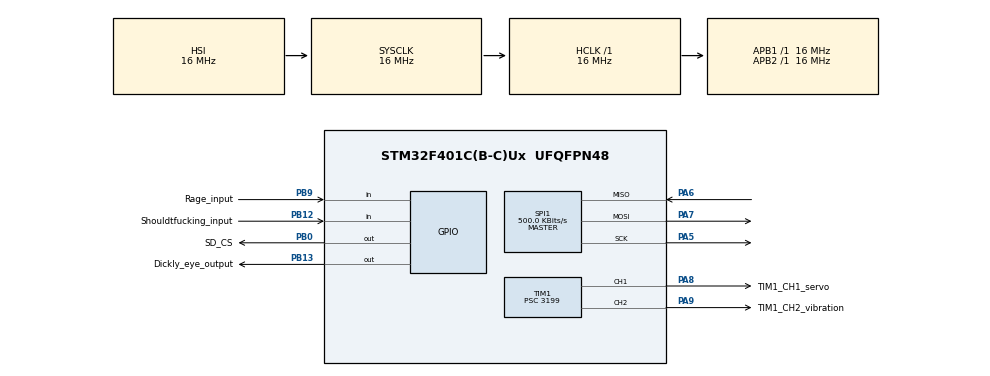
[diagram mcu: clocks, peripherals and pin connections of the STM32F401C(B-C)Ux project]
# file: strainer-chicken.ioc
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Mcu.Family=STM32F4
Mcu.Name=STM32F401C(B-C)Ux
Mcu.Package=UFQFPN48
NVIC.PriorityGroup=NVIC_PRIORITYGROUP_4
PA5.Mode=Full_Duplex_Master
PA5.Signal=SPI1_SCK
PA6.Mode=Full_Duplex_Master
PA6.Signal=SPI1_MISO
PA7.Mode=Full_Duplex_Master
PA7.Signal=SPI1_MOSI
PA8.GPIO_Label=TIM1_CH1_servo
PA8.Signal=S_TIM1_CH1
PA9.GPIO_Label=TIM1_CH2_vibration
PA9.Signal=S_TIM1_CH2
PB0.GPIO_Label=SD_CS
PB0.Signal=GPIO_Output
PB12.GPIO_Label=Shouldtfucking_input
PB12.Signal=GPIO_Input
PB13.GPIO_Label=Dickly_eye_output
PB13.Signal=GPIO_Output
PB9.GPIO_Label=Rage_input
PB9.Signal=GPIO_Input
ProjectManager.HeapSize=0x200
ProjectManager.StackSize=0x400
ProjectManager.TargetToolchain=STM32CubeIDE
RCC.AHBFreq_Value=16000000
RCC.APB1Freq_Value=16000000
RCC.APB2Freq_Value=16000000
RCC.CortexFreq_Value=16000000
RCC.HSE_VALUE=25000000
RCC.HSI_VALUE=16000000
RCC.LSE_VALUE=32768
RCC.SYSCLKFreq_VALUE=16000000
RCC.VCOOutputFreq_Value=192000000
SH.S_TIM1_CH1.0=TIM1_CH1,Output Compare1 CH1
SH.S_TIM1_CH2.0=TIM1_CH2,Output Compare2 CH2
SPI1.BaudRatePrescaler=SPI_BAUDRATEPRESCALER_32
SPI1.CalculateBaudRate=500.0 KBits/s
SPI1.Direction=SPI_DIRECTION_2LINES
SPI1.Mode=SPI_MODE_MASTER
SPI1.VirtualType=VM_MASTER
TIM1.Channel-Output\ Compare1\ CH1=TIM_CHANNEL_1
TIM1.Channel-Output\ Compare2\ CH2=TIM_CHANNEL_2
TIM1.Period=99
TIM1.Prescaler=3199
VP_FATFS_VS_Generic.Mode=User_defined
VP_TIM1_VS_ClockSourceINT.Mode=Internal
board=custom

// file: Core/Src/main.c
/* USER CODE BEGIN Header */
/**
  ******************************************************************************
  * @file           : main.c
  * @brief          : Main program body
  ******************************************************************************
  * @attention
  *
  * Copyright (c) 2023 STMicroelectronics.
  * All rights reserved.
  *
  * This software is licensed under terms that can be found in the LICENSE file
  * in the root directory of this software component.
  * If no LICENSE file comes with this software, it is provided AS-IS.
  *
  ******************************************************************************
  */
/* USER CODE END Header */
#include "main.h"
#include "fatfs.h"

SPI_HandleTypeDef hspi1;

TIM_HandleTypeDef htim1;

void SystemClock_Config(void);
static void MX_GPIO_Init(void);
static void MX_SPI1_Init(void);
static void MX_TIM1_Init(void);

int main(void)
{

  /* MCU Configuration--------------------------------------------------------*/

  /* Reset of all peripherals, Initializes the Flash interface and the Systick. */
  HAL_Init();

  /* Configure the system clock */
  SystemClock_Config();

  /* Initialize all configured peripherals */
  MX_GPIO_Init();
  MX_FATFS_Init();
  MX_SPI1_Init();
  MX_TIM1_Init();
  /* USER CODE BEGIN 2 */
  HAL_Delay(1000);

  FATFS FatFs; 	//Fatfs handle
  FIL fil; 		//File handle
  FRESULT fres; //Result after operations
  //TODO from https://01001000.xyz/2020-08-09-Tutorial-STM32CubeIDE-SD-card/

  /* USER CODE END 2 */

  /* Infinite loop */
  while (1)
  {

  }
}

void SystemClock_Config(void)
{
  RCC_OscInitTypeDef RCC_OscInitStruct = {0};
  RCC_ClkInitTypeDef RCC_ClkInitStruct = {0};

  /** Configure the main internal regulator output voltage
  */
  __HAL_RCC_PWR_CLK_ENABLE();
  __HAL_PWR_VOLTAGESCALING_CONFIG(PWR_REGULATOR_VOLTAGE_SCALE2);

  /** Initializes the RCC Oscillators according to the specified parameters
  * in the RCC_OscInitTypeDef structure.
  */
  RCC_OscInitStruct.OscillatorType = RCC_OSCILLATORTYPE_HSI;
  RCC_OscInitStruct.HSIState = RCC_HSI_ON;
  RCC_OscInitStruct.HSICalibrationValue = RCC_HSICALIBRATION_DEFAULT;
  RCC_OscInitStruct.PLL.PLLState = RCC_PLL_NONE;
  if (HAL_RCC_OscConfig(&RCC_OscInitStruct) != HAL_OK)
  {
    Error_Handler();
  }

  /** Initializes the CPU, AHB and APB buses clocks
  */
  RCC_ClkInitStruct.ClockType = RCC_CLOCKTYPE_HCLK|RCC_CLOCKTYPE_SYSCLK
                              |RCC_CLOCKTYPE_PCLK1|RCC_CLOCKTYPE_PCLK2;
  RCC_ClkInitStruct.SYSCLKSource = RCC_SYSCLKSOURCE_HSI;
  RCC_ClkInitStruct.AHBCLKDivider = RCC_SYSCLK_DIV1;
  RCC_ClkInitStruct.APB1CLKDivider = RCC_HCLK_DIV1;
  RCC_ClkInitStruct.APB2CLKDivider = RCC_HCLK_DIV1;

  if (HAL_RCC_ClockConfig(&RCC_ClkInitStruct, FLASH_LATENCY_0) != HAL_OK)
  {
    Error_Handler();
  }
}

static void MX_SPI1_Init(void)
{

  /* SPI1 parameter configuration*/
  hspi1.Instance = SPI1;
  hspi1.Init.Mode = SPI_MODE_MASTER;
  hspi1.Init.Direction = SPI_DIRECTION_2LINES;
  hspi1.Init.DataSize = SPI_DATASIZE_8BIT;
  hspi1.Init.CLKPolarity = SPI_POLARITY_LOW;
  hspi1.Init.CLKPhase = SPI_PHASE_1EDGE;
  hspi1.Init.NSS = SPI_NSS_SOFT;
  hspi1.Init.BaudRatePrescaler = SPI_BAUDRATEPRESCALER_32;
  hspi1.Init.FirstBit = SPI_FIRSTBIT_MSB;
  hspi1.Init.TIMode = SPI_TIMODE_DISABLE;
  hspi1.Init.CRCCalculation = SPI_CRCCALCULATION_DISABLE;
  hspi1.Init.CRCPolynomial = 10;
  if (HAL_SPI_Init(&hspi1) != HAL_OK)
  {
    Error_Handler();
  }

}

static void MX_TIM1_Init(void)
{

  TIM_ClockConfigTypeDef sClockSourceConfig = {0};
  TIM_MasterConfigTypeDef sMasterConfig = {0};
  TIM_OC_InitTypeDef sConfigOC = {0};
  TIM_BreakDeadTimeConfigTypeDef sBreakDeadTimeConfig = {0};

  htim1.Instance = TIM1;
  htim1.Init.Prescaler = 3199;
  htim1.Init.CounterMode = TIM_COUNTERMODE_UP;
  htim1.Init.Period = 99;
  htim1.Init.ClockDivision = TIM_CLOCKDIVISION_DIV1;
  htim1.Init.RepetitionCounter = 0;
  htim1.Init.AutoReloadPreload = TIM_AUTORELOAD_PRELOAD_DISABLE;
  if (HAL_TIM_Base_Init(&htim1) != HAL_OK)
  {
    Error_Handler();
  }
  sClockSourceConfig.ClockSource = TIM_CLOCKSOURCE_INTERNAL;
  if (HAL_TIM_ConfigClockSource(&htim1, &sClockSourceConfig) != HAL_OK)
  {
    Error_Handler();
  }
  if (HAL_TIM_OC_Init(&htim1) != HAL_OK)
  {
    Error_Handler();
  }
  sMasterConfig.MasterOutputTrigger = TIM_TRGO_RESET;
  sMasterConfig.MasterSlaveMode = TIM_MASTERSLAVEMODE_DISABLE;
  if (HAL_TIMEx_MasterConfigSynchronization(&htim1, &sMasterConfig) != HAL_OK)
  {
    Error_Handler();
  }
  sConfigOC.OCMode = TIM_OCMODE_TIMING;
  sConfigOC.Pulse = 0;
  sConfigOC.OCPolarity = TIM_OCPOLARITY_HIGH;
  sConfigOC.OCNPolarity = TIM_OCNPOLARITY_HIGH;
  sConfigOC.OCFastMode = TIM_OCFAST_DISABLE;
  sConfigOC.OCIdleState = TIM_OCIDLESTATE_RESET;
  sConfigOC.OCNIdleState = TIM_OCNIDLESTATE_RESET;
  if (HAL_TIM_OC_ConfigChannel(&htim1, &sConfigOC, TIM_CHANNEL_1) != HAL_OK)
  {
    Error_Handler();
  }
  if (HAL_TIM_OC_ConfigChannel(&htim1, &sConfigOC, TIM_CHANNEL_2) != HAL_OK)
  {
    Error_Handler();
  }
  sBreakDeadTimeConfig.OffStateRunMode = TIM_OSSR_DISABLE;
  sBreakDeadTimeConfig.OffStateIDLEMode = TIM_OSSI_DISABLE;
  sBreakDeadTimeConfig.LockLevel = TIM_LOCKLEVEL_OFF;
  sBreakDeadTimeConfig.DeadTime = 0;
  sBreakDeadTimeConfig.BreakState = TIM_BREAK_DISABLE;
  sBreakDeadTimeConfig.BreakPolarity = TIM_BREAKPOLARITY_HIGH;
  sBreakDeadTimeConfig.AutomaticOutput = TIM_AUTOMATICOUTPUT_DISABLE;
  if (HAL_TIMEx_ConfigBreakDeadTime(&htim1, &sBreakDeadTimeConfig) != HAL_OK)
  {
    Error_Handler();
  }
  HAL_TIM_MspPostInit(&htim1);

}

static void MX_GPIO_Init(void)
{
  GPIO_InitTypeDef GPIO_InitStruct = {0};

  /* GPIO Ports Clock Enable */
  __HAL_RCC_GPIOA_CLK_ENABLE();
  __HAL_RCC_GPIOB_CLK_ENABLE();

  /*Configure GPIO pin Output Level */
  HAL_GPIO_WritePin(GPIOB, SD_CS_Pin|Dickly_eye_output_Pin, GPIO_PIN_RESET);

  /*Configure GPIO pins : SD_CS_Pin Dickly_eye_output_Pin */
  GPIO_InitStruct.Pin = SD_CS_Pin|Dickly_eye_output_Pin;
  GPIO_InitStruct.Mode = GPIO_MODE_OUTPUT_PP;
  GPIO_InitStruct.Pull = GPIO_NOPULL;
  GPIO_InitStruct.Speed = GPIO_SPEED_FREQ_LOW;
  HAL_GPIO_Init(GPIOB, &GPIO_InitStruct);

  /*Configure GPIO pins : Shouldtfucking_input_Pin Rage_input_Pin */
  GPIO_InitStruct.Pin = Shouldtfucking_input_Pin|Rage_input_Pin;
  GPIO_InitStruct.Mode = GPIO_MODE_INPUT;
  GPIO_InitStruct.Pull = GPIO_NOPULL;
  HAL_GPIO_Init(GPIOB, &GPIO_InitStruct);

}

void Error_Handler(void)
{
  __disable_irq();
  while (1)
  {
  }
}
